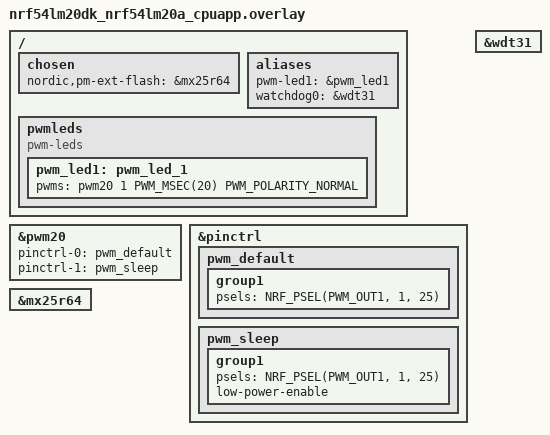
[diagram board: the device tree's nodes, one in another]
/*
 * Copyright (c) 2025 Nordic Semiconductor ASA
 *
 * SPDX-License-Identifier: LicenseRef-Nordic-5-Clause
 */

#include <nrf54lm20_cpuapp_partitions.dtsi>

/ {
	chosen {
		nordic,pm-ext-flash = &mx25r64;
	};

	aliases {
		/* Configure PWM module for led1 (LED2 on the board) */
		pwm-led1 = &pwm_led1;

		/* Use watchdog wdt31 as the application watchdog */
		watchdog0 = &wdt31;
	};

	pwmleds {
		compatible = "pwm-leds";

		pwm_led1: pwm_led_1 {
			pwms = <&pwm20 1 PWM_MSEC(20) PWM_POLARITY_NORMAL>;
		};
	};
};

&pwm20 {
	status = "okay";
	pinctrl-0 = <&pwm_default>;
	pinctrl-1 = <&pwm_sleep>;
	pinctrl-names = "default", "sleep";
};

&pinctrl {
	pwm_default: pwm_default {
		group1 {
			psels = <NRF_PSEL(PWM_OUT1, 1, 25)>;
		};
	};

	pwm_sleep: pwm_sleep {
		group1 {
			psels = <NRF_PSEL(PWM_OUT1, 1, 25)>;
			low-power-enable;
		};
	};
};

&mx25r64 {
	status = "okay";
};

&wdt31 {
	status = "okay";
};
